# STM32H7P5xx register map
File version: 1.0
Registers are 32-bit, read-write, reset 0x0 unless marked. A register's access mark holds for its fields unless they carry their own. Offsets are from the block's base; [hi:lo] are bit positions.

## WWDG — Window Watchdog
Base 0x40002C00
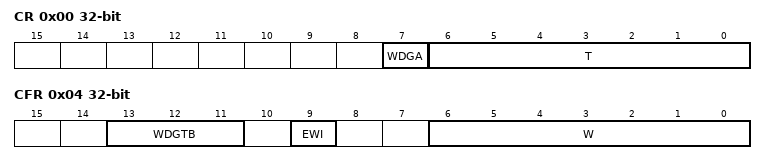
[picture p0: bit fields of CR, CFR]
0x00 CR — WWDG Control register
  [7] WDGA — Activation bit
  [6:0] T — T[6:0] bits (7-Bit counter (MSB to LSB))
0x04 CFR — WWDG Configuration register
  [13:11] WDGTB — WDGTB[2:0] bits (Timer Base)
  [9] EWI — Early Wakeup Interrupt
  [6:0] W — W[6:0] bits (7-bit window value)
0x08 SR — WWDG Status register
  [0] EWIF — Early Wakeup Interrupt Flag

## CRS — Clock Recovery System
Base 0x40008400
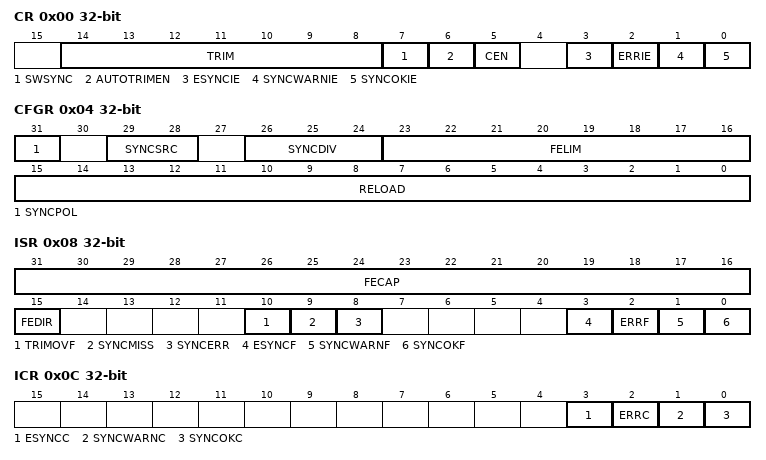
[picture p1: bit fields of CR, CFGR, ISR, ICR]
0x00 CR — CRS control register
  [14:8] TRIM — MCG48 oscillator smooth trimming
  [7] SWSYNC — Generate software SYNC event
  [6] AUTOTRIMEN — Automatic trimming enable
  [5] CEN — Frequency error counter enable
  [3] ESYNCIE — Expected SYNC interrupt enable
  [2] ERRIE — SYNC error or trimming error interrupt enable
  [1] SYNCWARNIE — SYNC warning interrupt enable
  [0] SYNCOKIE — SYNC event OK interrupt enable
0x04 CFGR — CRS configuration register
  [31] SYNCPOL — SYNC polarity selection
  [29:28] SYNCSRC — SYNC signal source selection
  [26:24] SYNCDIV — SYNC divider
  [23:16] FELIM — Frequency error limit
  [15:0] RELOAD — Counter reload value
0x08 ISR ro — CRS interrupt and status register
  [31:16] FECAP — Frequency error capture
  [15] FEDIR — Frequency error direction
  [10] TRIMOVF — Trimming overflow or underflow
  [9] SYNCMISS — SYNC missed
  [8] SYNCERR — SYNC error
  [3] ESYNCF — Expected SYNC flag
  [2] ERRF — Error flag
  [1] SYNCWARNF — SYNC warning flag
  [0] SYNCOKF — SYNC event OK flag
0x0C ICR — CRS interrupt flag clear register
  [3] ESYNCC — Expected SYNC clear flag
  [2] ERRC — Error clear flag
  [1] SYNCWARNC — SYNC warning clear flag
  [0] SYNCOKC — SYNC event OK clear flag

## FDCAN_CONFIG — FD Controller Area Network Configuration
Base 0x4000A100
0x00 CKDIV — FDCAN clock divider register
  [3:0] PDIV — input clock divider

## CORDIC
Base 0x48004400
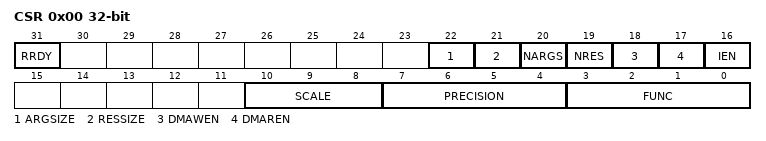
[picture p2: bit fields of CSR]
0x00 CSR — CORDIC control and status register
  [31] RRDY — Result Ready Flag
  [22] ARGSIZE — Width of input data
  [21] RESSIZE — Width of output data
  [20] NARGS — Number of arguments in RDATA register
  [19] NRES — Number of results in WDATA register
  [18] DMAWEN — DMA Write channel Enable
  [17] DMAREN — DMA Read channel Enable
  [16] IEN — Interrupt Enable
  [10:8] SCALE — Scaling factor
  [7:4] PRECISION
  [3:0] FUNC — Function
0x04 WDATA — CORDIC argument register
  [31:0] ARG — Input Argument
0x08 RDATA ro — CORDIC result register
  [31:0] RES — Output Result

## FMAC1 — Filter Mathematical ACcelerator unit (FMAC)
Base 0x48004800
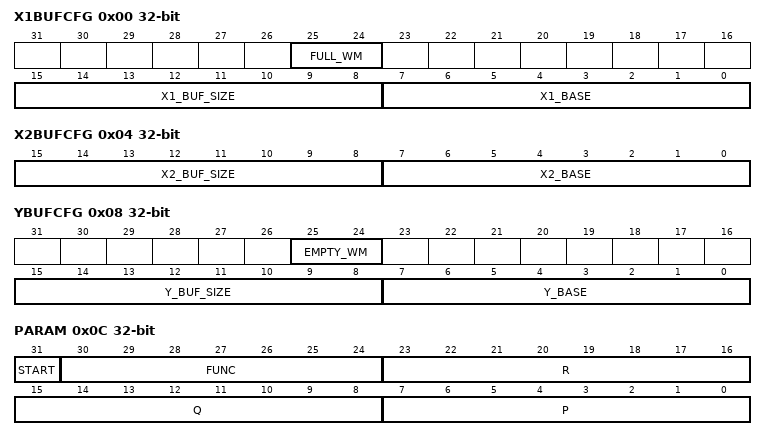
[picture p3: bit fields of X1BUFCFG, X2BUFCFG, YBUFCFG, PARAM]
0x00 X1BUFCFG — FMAC X1 Buffer Configuration register
  [25:24] FULL_WM — Watermark for buffer full flag
  [15:8] X1_BUF_SIZE — Allocated size of X1 buffer in 16-bit words
  [7:0] X1_BASE — Base address of X1 buffer
0x04 X2BUFCFG — FMAC X2 Buffer Configuration register
  [15:8] X2_BUF_SIZE — Size of X2 buffer in 16-bit words
  [7:0] X2_BASE — Base address of X2 buffer
0x08 YBUFCFG — FMAC Y Buffer Configuration register
  [25:24] EMPTY_WM — Watermark for buffer empty flag
  [15:8] Y_BUF_SIZE — Size of Y buffer in 16-bit words
  [7:0] Y_BASE — Base address of Y buffer
0x0C PARAM — FMAC Parameter register
  [31] START — Enable execution
  [30:24] FUNC — Function
  [23:16] R — Input parameter R
  [15:8] Q — Input parameter Q
  [7:0] P — Input parameter P
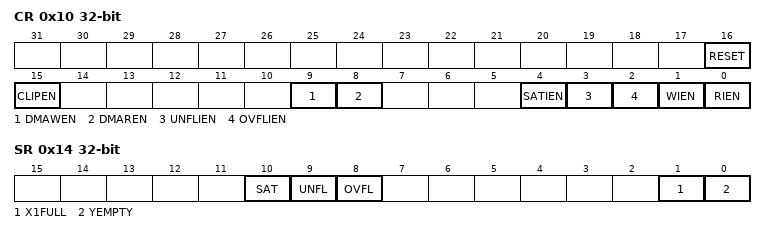
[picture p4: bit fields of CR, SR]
0x10 CR — FMAC Control register
  [16] RESET — Reset filter mathematical accelerator unit
  [15] CLIPEN — Enable clipping
  [9] DMAWEN — Enable DMA write channel requests
  [8] DMAREN — Enable DMA read channel requests
  [4] SATIEN — Enable saturation error interrupts
  [3] UNFLIEN — Enable underflow error interrupts
  [2] OVFLIEN — Enable overflow error interrupts
  [1] WIEN — Enable write interrupt
  [0] RIEN — Enable read interrupt
0x14 SR ro — FMAC Status register
  [10] SAT — Saturation error flag
  [9] UNFL — Underflow error flag
  [8] OVFL — Overflow error flag
  [1] X1FULL — X1 buffer full flag
  [0] YEMPTY — Y buffer empty flag
0x18 WDATA — FMAC Write Data register
  [15:0] WDATA — Write data
0x1C RDATA ro — FMAC Read Data register
  [15:0] RDATA — Read data
